# PIC32MX174F256D device description
Architecture: MIPS; Family: PIC32MX; Series: PIC32MX
Registers are 32-bit, read-write, no defined reset value unless marked. A register's access mark holds for its fields unless they carry their own. Offsets are from the block's base; [hi:lo] are bit positions; {n}, {i} and the like mark numbered series.

## BMX
Instances: BMX 0x1f882000 in periph2
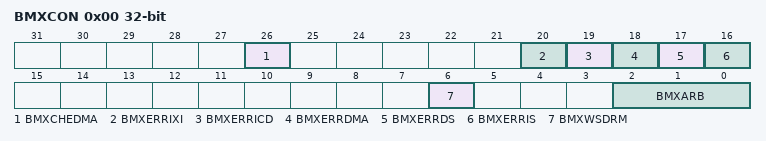
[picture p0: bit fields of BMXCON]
0x00 BMXCON — Bus Matrix Configuration Register
  [26] BMXCHEDMA — BMX PFM Cacheability for DMA Accesses bit
    1=Enable program Flash memory (data) cacheability for DMA accesses (requires cache to have data caching enabled); 0=Disable program Flash memory (data) cacheability for DMA accesses(hits are still read from the cache
  [20] BMXERRIXI — Enable Bus Error from IXI bit
    1=Enable bus error exceptions for unmapped address accesses initiated from IXI shared bus; 0=Disable bus error exceptions for unmapped address accesses initiated from IXI shared bus
  [19] BMXERRICD — Enable Bus Error from ICD Debug Unit bit
    1=Enable bus error exceptions for unmapped address accesses initiated from ICD; 0=Disable bus error exceptions for unmapped address accesses initiated from ICD
  [18] BMXERRDMA — Bus Error from DMA bit
    1=Enable bus error exceptions for unmapped address accesses initiated from DMA; 0=Disable bus error exceptions for unmapped address accesses initiated from DMA
  [17] BMXERRDS — Bus Error from CPU Data Access bit
    1=Enable bus error exceptions for unmapped address accesses initiated from CPU data access; 0=Disable bus error exceptions for unmapped address accesses initiated from CPU data access
  [16] BMXERRIS — Bus Error from CPU Instruction Access bit
    1=Enable bus error exceptions for unmapped address accesses initiated from CPU instruction access; 0=Disable bus error exceptions for unmapped address accesses initiated from CPU instruction access
  [6] BMXWSDRM — CPU Instruction or Data Access from Data RAM Wait State bit
    1=Data RAM accesses from CPU have one wait state for address setup; 0=Data RAM accesses from CPU have zero wait states for address setup
  [2:0] BMXARB — Bus Matrix Arbitration Mode bits
    2=Arbitration Mode 2; 1=Arbitration Mode 1 (default); 0=Arbitration Mode 0
0x10 BMXDKPBA — Data RAM Kernel Program Base Address Register
  [31:0] BMXDKPBA — DRM Kernel Program Base Address bits (bits 15-10, bits 9-0 are read only)
    0=No relative base address set
0x20 BMXDUDBA — Data RAM User Data Base Address Register
  [31:0] BMXDUDBA — DRM User Data Base Address bits (bits 15-10, bits 9-0 are read only)
    0=No relative base address set
0x30 BMXDUPBA — Data RAM User Program Base Address Register
  [31:0] BMXDUPBA — DRM User Program Base Address bits (bits 15-10, bits 9-0 are read only)
    0=No relative base address set
0x40 BMXDRMSZ ro — Data RAM Size Register
  [31:0] BMXDRMSZ — Data RAM Memory Size bits
    0x4000=Device has 16 KB RAM; 0x8000=Device has 32 KB RAM; 0x10000=Device has 64 KB RAM; 0x20000=Device has 128 KB RAM
0x50 BMXPUPBA — Program Flash (PFM) User Program Base Address Register
0x60 BMXPFMSZ ro — Program Flash (PFM) Size Register
  [31:0] BMXPFMSZ — Program Flash Memory (PFM) Size bits
    0x10000=Device has 64 KB Flash; 0x20000=Device has 128 KB Flash; 0x40000=Device has 256 KB Flash; 0x80000=Device has 512 KB Flash
0x70 BMXBOOTSZ ro — Boot Flash (IFM) Size Register
  [31:0] BMXBOOTSZ — Boot Flash Memory Size bits
    0x3000=Device has 12 KB Boot Flash

## CFG
Instances: CFG 0x1f80f200 in periph1
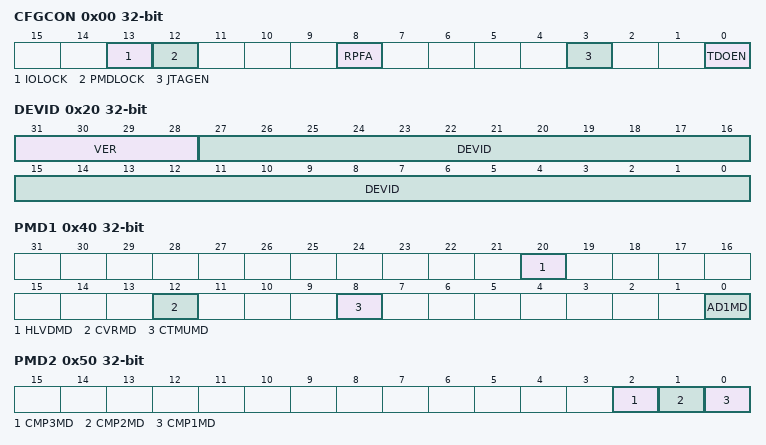
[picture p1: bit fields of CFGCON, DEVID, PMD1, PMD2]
0x00 CFGCON — Configuration Control Register
  [13] IOLOCK — Peripheral Pin Select Lock bit
    1=Peripheral Pin Select is locked. Writes to PPS registers is not allowed.; 0=Peripheral Pin Select is not locked. Writes to PPS registers is allowed.
  [12] PMDLOCK — Peripheral Module Disable bit
    1=Peripheral module is locked. Writes to PMD registers is not allowed.; 0=Peripheral module is not locked. Writes to PMD registers is allowed.
  [8] RPFA — Reduced Power Flash Access bit
    1=Enables Low Power Read Circuit; 0=Disables Low Power Read Circuit (which improves flash read access timing)
  [3] JTAGEN — JTAG Port Enable bit
    8=Enable the JTAG port; 0=Disable the JTAG port
  [0] TDOEN — TDO Enable for 2-Wire JTAG bit
    1=2-wire JTAG protocol uses TDO; 0=2-wire JTAG protocol does not use TDO
0x20 DEVID ro
  [31:28] VER, [27:0] DEVID
0x30 SYSKEY ro
0x40 PMD1
  [20] HLVDMD, [12] CVRMD, [8] CTMUMD, [0] AD1MD
0x50 PMD2
  [2] CMP3MD, [1] CMP2MD, [0] CMP1MD
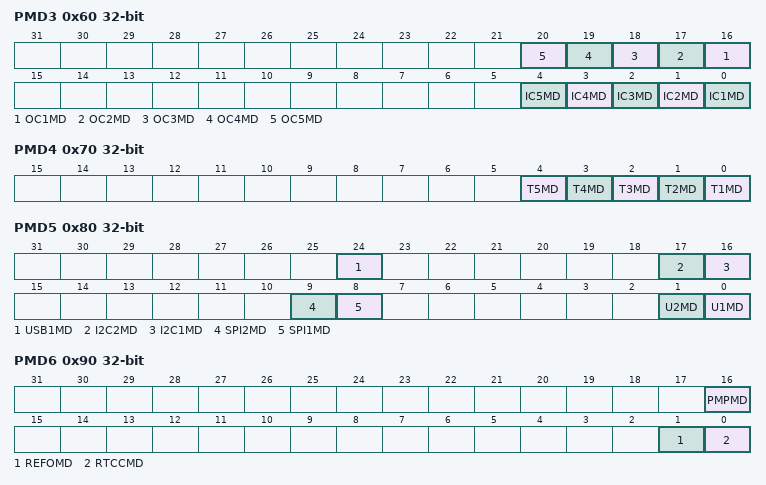
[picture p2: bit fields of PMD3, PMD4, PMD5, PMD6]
0x60 PMD3
  [n+15] OC{n}MD (n=1..5), [n-1] IC{n}MD (n=1..5)
0x70 PMD4
  [n-1] T{n}MD (n=1..5)
0x80 PMD5
  [24] USB1MD, [17] I2C2MD, [16] I2C1MD, [9] SPI2MD, [8] SPI1MD, [1] U2MD, [0] U1MD
0x90 PMD6
  [16] PMPMD, [1] REFOMD, [0] RTCCMD

## Notices in the file
Copyright (c) 2019 Microchip Technology Inc.
SPDX-License-Identifier: Apache-2.0
Licensed under the Apache License, Version 2.0 (the "License");
you may not use this file except in compliance with the License.
You may obtain a copy of the License at
http://www.apache.org/licenses/LICENSE-2.0
Unless required by applicable law or agreed to in writing, software
distributed under the License is distributed on an "AS IS" BASIS,
WITHOUT WARRANTIES OR CONDITIONS OF ANY KIND, either express or implied.
See the License for the specific language governing permissions and
limitations under the License.
